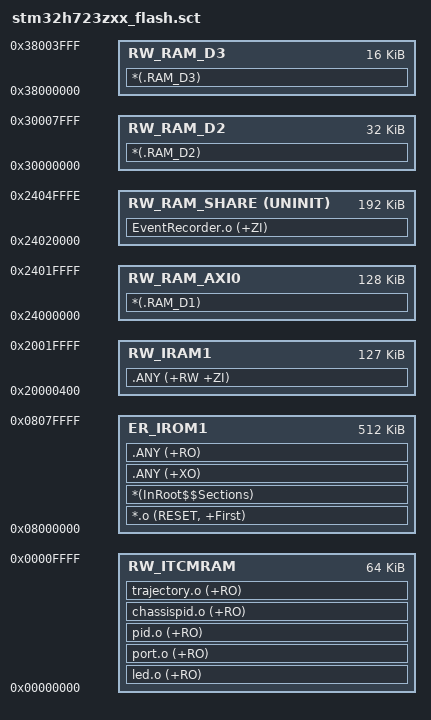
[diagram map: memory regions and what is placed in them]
; *********************************************************************************
; *** Scatter-Loading Description File generated by STM32CubeMX/LinkerGenerator ***
; *********************************************************************************;

LR_IROM1 0x08000000 0x00080000  {  ; load_region size_region

  ER_IROM1 0x08000000 0x00080000  {  ; load address = excetion address
   *.o (RESET, +First)
   *(InRoot$$Sections)
   .ANY (+XO)
   .ANY (+RO)
  }
  RW_IRAM1 0x20000400 0x0001FC00  {  ; load address = excetion address
   .ANY (+RW +ZI)
  }
  RW_RAM_AXI0 0x24000000 0x00020000  {  ; load address = excetion address
   *(.RAM_D1)
  }
  RW_RAM_SHARE 0x24020000 UNINIT 0x0002FFFF  {  ; load address = excetion address
   EventRecorder.o (+ZI)
  }
  RW_RAM_D2 0x30000000 0x00008000  {  ; load address = excetion address
   *(.RAM_D2)
  }
  RW_RAM_D3 0x38000000 0x00004000  {  ; load address = excetion address
   *(.RAM_D3)
  }
  RW_ITCMRAM 0x00000000 0x00010000  {  ; load address = excetion address
   led.o (+RO)
   port.o (+RO)
   pid.o (+RO)
   chassispid.o (+RO)
   trajectory.o (+RO)
  }
}

